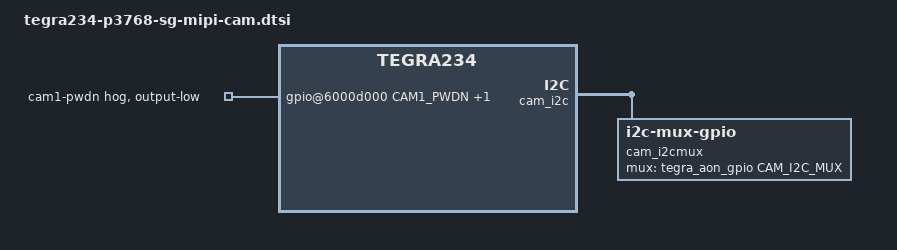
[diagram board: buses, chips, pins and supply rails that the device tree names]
/*
 * Copyright (c) 2022, NVIDIA CORPORATION.  All rights reserved.
 *
 * This program is free software; you can redistribute it and/or modify
 * it under the terms of the GNU General Public License as published by
 * the Free Software Foundation; either version 2 of the License, or
 * (at your option) any later version.
 *
 * This program is distributed in the hope that it will be useful, but WITHOUT
 * ANY WARRANTY; without even the implied warranty of MERCHANTABILITY or
 * FITNESS FOR A PARTICULAR PURPOSE.  See the GNU General Public License for
 * more details.
 *
 * You should have received a copy of the GNU General Public License
 * along with this program.  If not, see <http://www.gnu.org/licenses/>.
 */

#include "sg-mipi-imx662-4lane.dtsi"

/ {
	cam_i2cmux {
		compatible = "i2c-mux-gpio";
		#address-cells = <1>;
		#size-cells = <0>;
		mux-gpios = <&tegra_aon_gpio CAM_I2C_MUX GPIO_ACTIVE_HIGH>;
		i2c-parent = <&cam_i2c>;
		i2c@0 {
			reg = <0>;
			#address-cells = <1>;
			#size-cells = <0>;
		};
		i2c@1 {
			reg = <1>;
			#address-cells = <1>;
			#size-cells = <0>;
		};
	};

	gpio@6000d000 {
		camera-control-output-low {
			gpio-hog;
			output-low;
			gpios = < CAM1_PWDN 0  CAM0_PWDN 0>;
			label = "cam1-pwdn", "cam0-pwdn";
		};
	};
};
